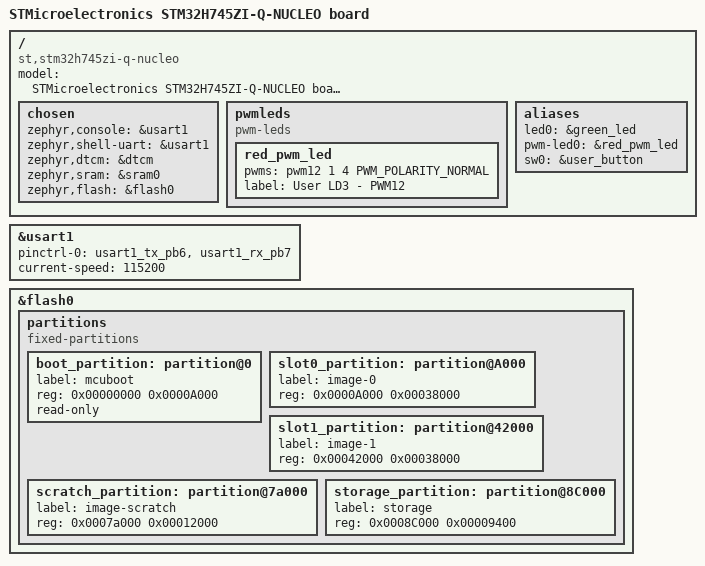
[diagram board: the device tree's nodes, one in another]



/ {
	model = "STMicroelectronics STM32H745ZI-Q-NUCLEO board";
	compatible = "st,stm32h745zi-q-nucleo";

	/* HW resources belonging to CM7 */
	chosen {
		zephyr,console = &usart1;
		zephyr,shell-uart = &usart1;
		zephyr,dtcm = &dtcm;
		zephyr,sram = &sram0;
		zephyr,flash = &flash0;
		// zephyr,code-partition = &slot0_partition;
	};

	pwmleds {
		compatible = "pwm-leds";

		red_pwm_led: red_pwm_led {
			pwms = <&pwm12 1 4 PWM_POLARITY_NORMAL>;
			label = "User LD3 - PWM12";
		};
	};

	aliases {
		led0 = &green_led;
		pwm-led0 = &red_pwm_led;
		sw0 = &user_button;
	};
};

&usart1 {
	pinctrl-0 = <&usart1_tx_pb6 &usart1_rx_pb7>;
	current-speed = <115200>;
	status = "okay";
};

&flash0 {

	partitions {
		compatible = "fixed-partitions";
		#address-cells = <1>;
		#size-cells = <1>;
		/* Please enable mcuboot's swap move, no scratch */

		boot_partition: partition@0 {
			label = "mcuboot";
			reg = <0x00000000 0x0000A000>;
			read-only;
		};

		slot0_partition: partition@A000 {
			label = "image-0";
			reg = <0x0000A000 0x00038000>;
			// reg = <0x00000000 0x00038000>;
		};
		slot1_partition: partition@42000 {
			label = "image-1";
			reg = <0x00042000 0x00038000>;
		};
		scratch_partition: partition@7a000  {
			label = "image-scratch";
			reg = <0x0007a000 0x00012000>;
		};
		storage_partition: partition@8C000 {
			label = "storage";
			reg = <0x0008C000 0x00009400>;
		};
	};
};
